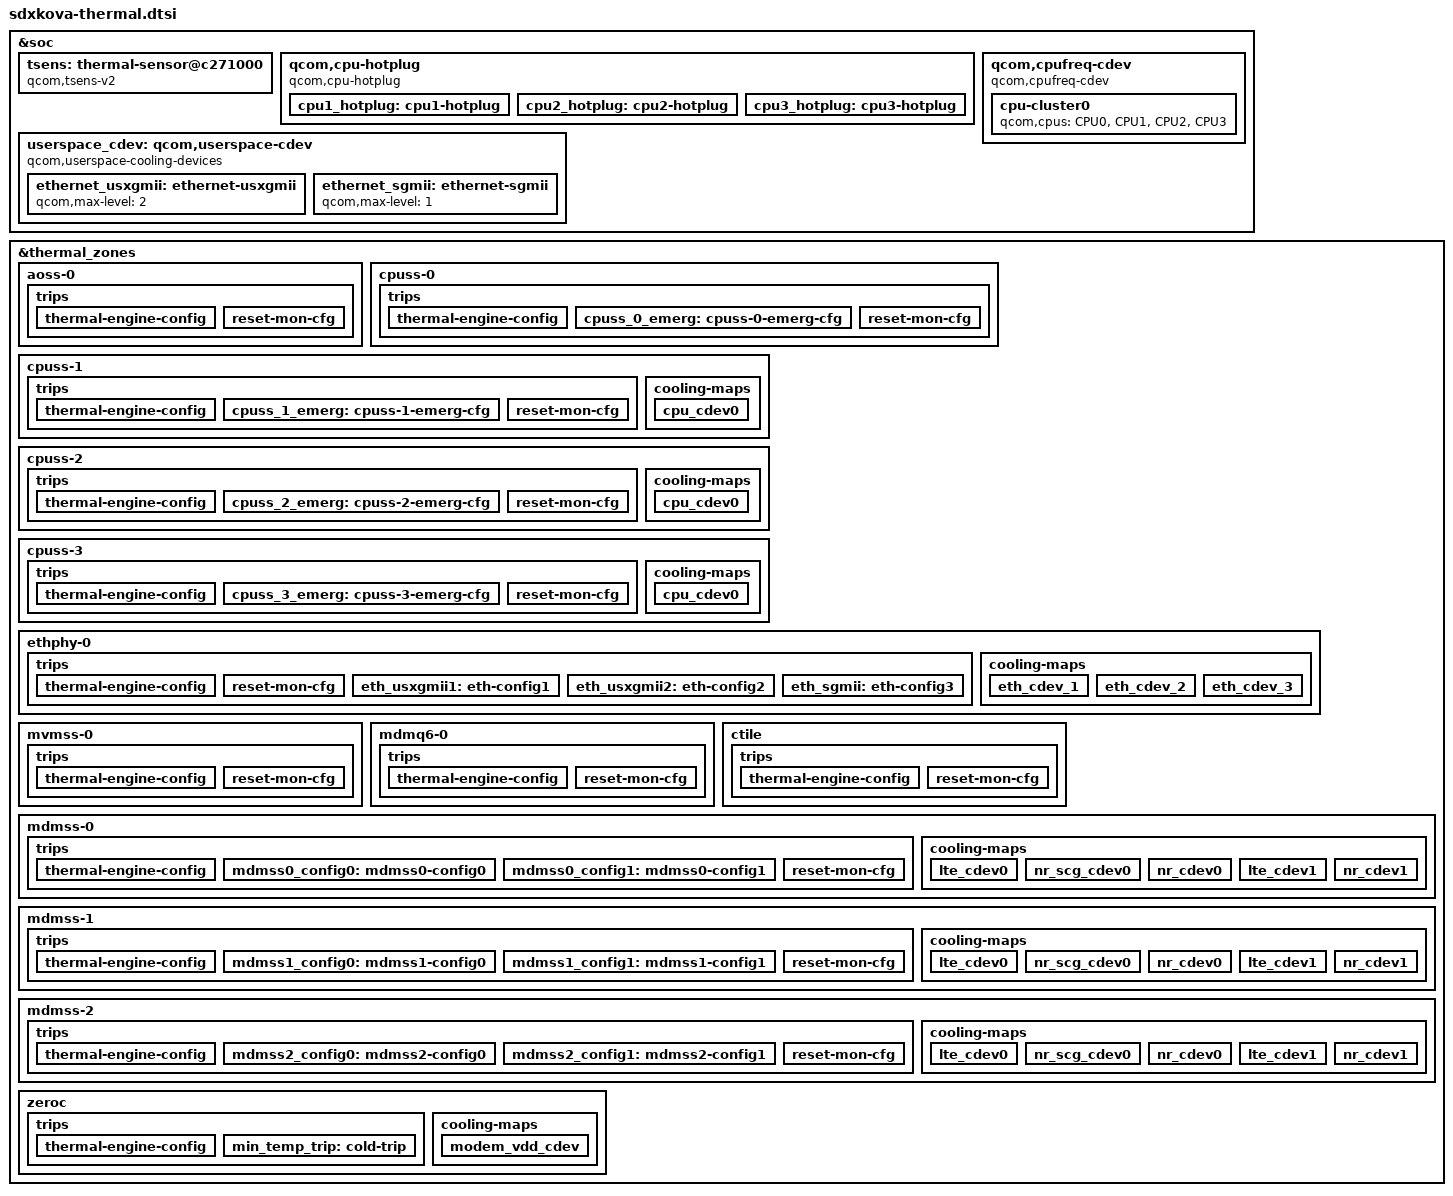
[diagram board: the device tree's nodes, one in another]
// SPDX-License-Identifier: BSD-3-Clause
/*
 * Copyright (c) 2024-2025 Qualcomm Innovation Center, Inc. All rights reserved.
 */

#include <dt-bindings/thermal/thermal_qti.h>

&soc {
	tsens: thermal-sensor@c271000 {
		compatible = "qcom,tsens-v2";
		reg = <0x0 0x0c271000 0x0 0x1ff>, /* TM */
			<0x0 0x0c222000 0x0 0x1ff>; /* SROT */
		#qcom,sensors = <12>;
		interrupts-extended = <&intc GIC_SPI 173 IRQ_TYPE_LEVEL_HIGH>,
			     <&intc GIC_SPI 333 IRQ_TYPE_LEVEL_HIGH>,
			     <&pdc 20 IRQ_TYPE_EDGE_RISING>;
		interrupt-names = "uplow", "critical", "cold";
		#thermal-sensor-cells = <1>;
	};

	qcom,cpu-hotplug {
		compatible = "qcom,cpu-hotplug";

		cpu1_hotplug: cpu1-hotplug {
			qcom,cpu = <&CPU1>;
			qcom,cdev-alias = "cpu-hotplug1";
			#cooling-cells = <2>;
		};

		cpu2_hotplug: cpu2-hotplug {
			qcom,cpu = <&CPU2>;
			qcom,cdev-alias = "cpu-hotplug2";
			#cooling-cells = <2>;
		};

		cpu3_hotplug: cpu3-hotplug {
			qcom,cpu = <&CPU3>;
			qcom,cdev-alias = "cpu-hotplug3";
			#cooling-cells = <2>;
		};
	};

	qcom,cpufreq-cdev {
		compatible = "qcom,cpufreq-cdev";
		cpu-cluster0 {
			qcom,cpus = <&CPU0 &CPU1 &CPU2 &CPU3>;
		};
	};

	userspace_cdev: qcom,userspace-cdev {
		compatible = "qcom,userspace-cooling-devices";

		ethernet_usxgmii: ethernet-usxgmii {
			/* Levels: USXGMII 10G, SGMII 2.5G, SGMII 1G */
			qcom,max-level = <2>;
			#cooling-cells = <2>;
		};

		ethernet_sgmii: ethernet-sgmii {
			/* Levels: SGMII 2.5G, SGMII 1G */
			qcom,max-level = <1>;
			#cooling-cells = <2>;
		};
	};
};

#include "sdxkova-thermal-modem.dtsi"

&thermal_zones {
	aoss-0 {
		polling-delay-passive = <0>;
		polling-delay = <0>;
		thermal-sensors = <&tsens 0>;
		trips {
			thermal-engine-config {
				temperature = <135000>;
				hysteresis = <5000>;
				type = "passive";
			};

			reset-mon-cfg {
				temperature = <125000>;
				hysteresis = <5000>;
				type = "passive";
			};
		};
	};

	cpuss-0 {
		polling-delay-passive = <0>;
		polling-delay = <0>;
		thermal-sensors = <&tsens 1>;
		trips {
			thermal-engine-config {
				temperature = <135000>;
				hysteresis = <5000>;
				type = "passive";
			};

			cpuss_0_emerg: cpuss-0-emerg-cfg {
				temperature = <110000>;
				hysteresis = <10000>;
				type = "passive";
			};

			reset-mon-cfg {
				temperature = <125000>;
				hysteresis = <5000>;
				type = "passive";
			};
		};
	};

	cpuss-1 {
		polling-delay-passive = <0>;
		polling-delay = <0>;
		thermal-sensors = <&tsens 2>;
		trips {
			thermal-engine-config {
				temperature = <135000>;
				hysteresis = <5000>;
				type = "passive";
			};

			cpuss_1_emerg: cpuss-1-emerg-cfg {
				temperature = <110000>;
				hysteresis = <10000>;
				type = "passive";
			};

			reset-mon-cfg {
				temperature = <125000>;
				hysteresis = <5000>;
				type = "passive";
			};
		};

		cooling-maps {
			cpu_cdev0 {
				trip = <&cpuss_1_emerg>;
				cooling-device = <&cpu1_hotplug 1 1>;
			};
		};
	};

	cpuss-2 {
		polling-delay-passive = <0>;
		polling-delay = <0>;
		thermal-sensors = <&tsens 3>;
		trips {
			thermal-engine-config {
				temperature = <135000>;
				hysteresis = <5000>;
				type = "passive";
			};

			cpuss_2_emerg: cpuss-2-emerg-cfg {
				temperature = <110000>;
				hysteresis = <10000>;
				type = "passive";
			};

			reset-mon-cfg {
				temperature = <125000>;
				hysteresis = <5000>;
				type = "passive";
			};
		};

		cooling-maps {
			cpu_cdev0 {
				trip = <&cpuss_2_emerg>;
				cooling-device = <&cpu2_hotplug 1 1>;
			};
		};
	};

	cpuss-3 {
		polling-delay-passive = <0>;
		polling-delay = <0>;
		thermal-sensors = <&tsens 4>;
		trips {
			thermal-engine-config {
				temperature = <135000>;
				hysteresis = <5000>;
				type = "passive";
			};

			cpuss_3_emerg: cpuss-3-emerg-cfg {
				temperature = <110000>;
				hysteresis = <10000>;
				type = "passive";
			};

			reset-mon-cfg {
				temperature = <125000>;
				hysteresis = <5000>;
				type = "passive";
			};
		};

		cooling-maps {
			cpu_cdev0 {
				trip = <&cpuss_3_emerg>;
				cooling-device = <&cpu3_hotplug 1 1>;
			};
		};
	};

	ethphy-0 {
		polling-delay-passive = <0>;
		polling-delay = <0>;
		thermal-sensors = <&tsens 5>;
		trips {
			thermal-engine-config {
				temperature = <135000>;
				hysteresis = <5000>;
				type = "passive";
			};

			reset-mon-cfg {
				temperature = <125000>;
				hysteresis = <5000>;
				type = "passive";
			};

			eth_usxgmii1: eth-config1 {
				temperature = <135000>;
				hysteresis = <5000>;
				type = "passive";
			};

			eth_usxgmii2: eth-config2 {
				temperature = <135000>;
				hysteresis = <5000>;
				type = "passive";
			};

			eth_sgmii: eth-config3 {
				temperature = <135000>;
				hysteresis = <5000>;
				type = "passive";
			};
		};

		cooling-maps {
			eth_cdev_1 {
				trip = <&eth_usxgmii1>;
				cooling-device = <&ethernet_usxgmii 1 1>;
			};

			eth_cdev_2 {
				trip = <&eth_usxgmii2>;
				cooling-device = <&ethernet_usxgmii 2 2>;
			};

			eth_cdev_3 {
				trip = <&eth_sgmii>;
				cooling-device = <&ethernet_sgmii 1 1>;
			};
		};
	};

	mvmss-0 {
		polling-delay-passive = <0>;
		polling-delay = <0>;
		thermal-sensors = <&tsens 6>;
		trips {
			thermal-engine-config {
				temperature = <135000>;
				hysteresis = <5000>;
				type = "passive";
			};

			reset-mon-cfg {
				temperature = <125000>;
				hysteresis = <5000>;
				type = "passive";
			};
		};
	};

	mdmq6-0 {
		polling-delay-passive = <0>;
		polling-delay = <0>;
		thermal-sensors = <&tsens 7>;
		trips {
			thermal-engine-config {
				temperature = <135000>;
				hysteresis = <5000>;
				type = "passive";
			};

			reset-mon-cfg {
				temperature = <125000>;
				hysteresis = <5000>;
				type = "passive";
			};
		};
	};

	ctile {
		polling-delay-passive = <0>;
		polling-delay = <0>;
		thermal-sensors = <&tsens 8>;
		trips {
			thermal-engine-config {
				temperature = <135000>;
				hysteresis = <5000>;
				type = "passive";
			};

			reset-mon-cfg {
				temperature = <125000>;
				hysteresis = <5000>;
				type = "passive";
			};
		};
	};

	mdmss-0 {
		polling-delay-passive = <100>;
		polling-delay = <0>;
		thermal-sensors = <&tsens 9>;
		trips {
			thermal-engine-config {
				temperature = <135000>;
				hysteresis = <5000>;
				type = "passive";
			};

			mdmss0_config0: mdmss0-config0 {
				temperature = <111000>;
				hysteresis = <3000>;
				type = "passive";
			};

			mdmss0_config1: mdmss0-config1 {
				temperature = <115000>;
				hysteresis = <3000>;
				type = "passive";
			};

			reset-mon-cfg {
				temperature = <125000>;
				hysteresis = <5000>;
				type = "passive";
			};
		};

		cooling-maps {
			lte_cdev0 {
				trip = <&mdmss0_config0>;
				cooling-device = <&modem_lte_dsc 8 8>;
			};

			nr_scg_cdev0 {
				trip = <&mdmss0_config0>;
				cooling-device = <&modem_nr_scg_dsc 12 12>;
			};

			nr_cdev0 {
				trip = <&mdmss0_config0>;
				cooling-device = <&modem_nr_dsc 8 8>;
			};

			lte_cdev1 {
				trip = <&mdmss0_config1>;
				cooling-device = <&modem_lte_dsc 255 255>;
			};

			nr_cdev1 {
				trip = <&mdmss0_config1>;
				cooling-device = <&modem_nr_dsc 255 255>;
			};
		};
	};

	mdmss-1 {
		polling-delay-passive = <100>;
		polling-delay = <0>;
		thermal-sensors = <&tsens 10>;
		trips {
			thermal-engine-config {
				temperature = <135000>;
				hysteresis = <5000>;
				type = "passive";
			};

			mdmss1_config0: mdmss1-config0 {
				temperature = <111000>;
				hysteresis = <3000>;
				type = "passive";
			};

			mdmss1_config1: mdmss1-config1 {
				temperature = <115000>;
				hysteresis = <3000>;
				type = "passive";
			};

			reset-mon-cfg {
				temperature = <125000>;
				hysteresis = <5000>;
				type = "passive";
			};
		};

		cooling-maps {
			lte_cdev0 {
				trip = <&mdmss1_config0>;
				cooling-device = <&modem_lte_dsc 8 8>;
			};

			nr_scg_cdev0 {
				trip = <&mdmss1_config0>;
				cooling-device = <&modem_nr_scg_dsc 12 12>;
			};

			nr_cdev0 {
				trip = <&mdmss1_config0>;
				cooling-device = <&modem_nr_dsc 8 8>;
			};

			lte_cdev1 {
				trip = <&mdmss1_config1>;
				cooling-device = <&modem_lte_dsc 255 255>;
			};

			nr_cdev1 {
				trip = <&mdmss1_config1>;
				cooling-device = <&modem_nr_dsc 255 255>;
			};
		};
	};

	mdmss-2 {
		polling-delay-passive = <100>;
		polling-delay = <0>;
		thermal-sensors = <&tsens 11>;
		trips {
			thermal-engine-config {
				temperature = <135000>;
				hysteresis = <5000>;
				type = "passive";
			};

			mdmss2_config0: mdmss2-config0 {
				temperature = <111000>;
				hysteresis = <3000>;
				type = "passive";
			};

			mdmss2_config1: mdmss2-config1 {
				temperature = <115000>;
				hysteresis = <3000>;
				type = "passive";
			};

			reset-mon-cfg {
				temperature = <125000>;
				hysteresis = <5000>;
				type = "passive";
			};
		};

		cooling-maps {
			lte_cdev0 {
				trip = <&mdmss2_config0>;
				cooling-device = <&modem_lte_dsc 8 8>;
			};

			nr_scg_cdev0 {
				trip = <&mdmss2_config0>;
				cooling-device = <&modem_nr_scg_dsc 12 12>;
			};

			nr_cdev0 {
				trip = <&mdmss2_config0>;
				cooling-device = <&modem_nr_dsc 8 8>;
			};

			lte_cdev1 {
				trip = <&mdmss2_config1>;
				cooling-device = <&modem_lte_dsc 255 255>;
			};

			nr_cdev1 {
				trip = <&mdmss2_config1>;
				cooling-device = <&modem_nr_dsc 255 255>;
			};
		};
	};

	zeroc {
		polling-delay-passive = <0>;
		polling-delay = <0>;
		thermal-sensors = <&tsens 128>;
		trips {
			thermal-engine-config {
				temperature = <1>;
				hysteresis = <1>;
				type = "passive";
			};

			min_temp_trip: cold-trip {
				temperature = <1>;
				hysteresis = <1>;
				type = "passive";
			};
		};

		cooling-maps {
			modem_vdd_cdev {
				trip = <&min_temp_trip>;
				cooling-device = <&modem_vdd 1 1>;
			};
		};
	};
};
